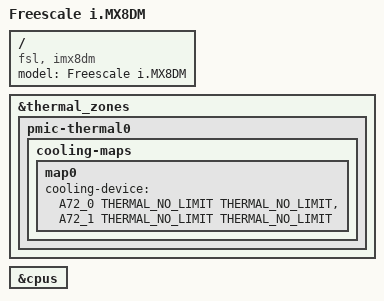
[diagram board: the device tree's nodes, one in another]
// SPDX-License-Identifier: GPL-2.0+
/*
 * Copyright 2019 NXP
 */

#include "imx8qm.dtsi"

/ {
        model = "Freescale i.MX8DM";
        compatible = "fsl, imx8dm", "fsl,imx8qm";

};

&thermal_zones {
	/delete-node/ cpu0-thermal;

	pmic-thermal0 {
		cooling-maps {
			map0 {
				cooling-device =
				<&A72_0 THERMAL_NO_LIMIT THERMAL_NO_LIMIT>,
				<&A72_1 THERMAL_NO_LIMIT THERMAL_NO_LIMIT>;
			};
		};
	};
};

&cpus {
	/delete-node/ cpu-map;
	/delete-node/ cpu@0;
	/delete-node/ cpu@1;
	/delete-node/ cpu@2;
	/delete-node/ cpu@3;
	/delete-node/ l2-cache0;
};
